# MSP430FR2475 register map
Vendor: msp430gen; File version: v0.4.0-28-gb0087ce-dirty
Registers are 16-bit, read-write, reset 0x0 unless marked. A register's access mark holds for its fields unless they carry their own. Offsets are from the block's base; [hi:lo] are bit positions; 'fields as' and 'values as' point back to an identical list.

## E_USCI_A1
Base 0x00000520
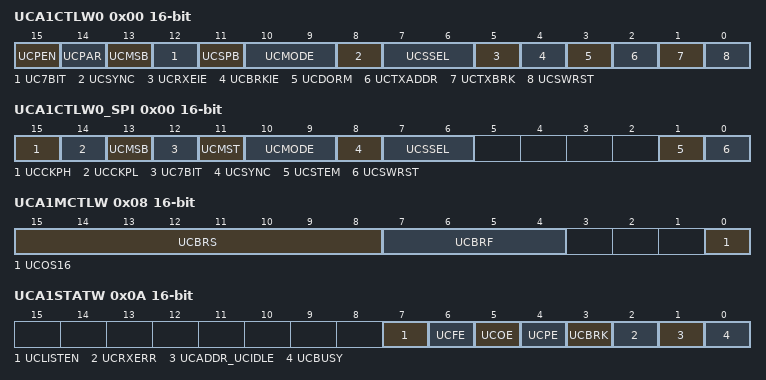
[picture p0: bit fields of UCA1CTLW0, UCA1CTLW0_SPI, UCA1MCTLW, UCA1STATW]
0x00 UCA1CTLW0 — eUSCI_Ax Control Word Register 0
  [15] UCPEN — Parity enable
    0=Parity disabled; 1=Parity enabled. Parity bit is generated (UCAxTXD) and expected (UCAxRXD). In address-bit multiprocessor mode, the address bit is included in the parity calculation.
  [14] UCPAR — Parity select
    0=ODD (Odd parity); 1=EVEN (Even parity)
  [13] UCMSB — MSB first select
    0=LSB first; 1=MSB first
  [12] UC7BIT — Character length
    0=8BIT (8-bit data); 1=7BIT (7-bit data)
  [11] UCSPB — Stop bit select
    0=One stop bit; 1=Two stop bits
  [10:9] UCMODE — eUSCI_A mode
    0=UART mode; 1=Idle-line multiprocessor mode; 2=Address-bit multiprocessor mode; 3=UART mode with automatic baud-rate detection
  [8] UCSYNC — Synchronous mode enable
    0=ASYNC (Asynchronous mode); 1=SYNC (Synchronous mode)
  [7:6] UCSSEL — eUSCI_A clock source select
    0=UCLK; 1=ACLK; 2=SMCLK; 3=SMCLK
  [5] UCRXEIE — Receive erroneous-character interrupt enable
    0=Erroneous characters rejected and UCRXIFG is not set; 1=Erroneous characters received set UCRXIFG
  [4] UCBRKIE — Receive break character interrupt enable
    0=Received break characters do not set UCRXIFG; 1=Received break characters set UCRXIFG
  [3] UCDORM — Dormant
    0=Not dormant. All received characters set UCRXIFG.; 1=Dormant. Only characters that are preceded by an idle-line or with address bit set UCRXIFG. In UART mode with automatic baud-rate detection, only the combination of a break and synch field sets UCRXIFG.
  [2] UCTXADDR — Transmit address
    0=Next frame transmitted is data; 1=Next frame transmitted is an address
  [1] UCTXBRK — Transmit break
    0=Next frame transmitted is not a break; 1=Next frame transmitted is a break or a break/synch
  [0] UCSWRST — Software reset enable
    0=DISABLE (Disabled. eUSCI_A reset released for operation); 1=ENABLE (Enabled. eUSCI_A logic held in reset state)
0x00 UCA1CTLW0_SPI (alternate view of UCA1CTLW0) — eUSCI_Ax Control Word Register 0
  [15] UCCKPH — Clock phase select
    0=Data is changed on the first UCLK edge and captured on the following edge; 1=Data is captured on the first UCLK edge and changed on the following edge
  [14] UCCKPL — Clock polarity select
    0=LOW (The inactive state is low); 1=HIGH (The inactive state is high)
  [13] UCMSB — MSB first select
    0=LSB first; 1=MSB first
  [12] UC7BIT — Character length
    0=8BIT (8-bit data); 1=7BIT (7-bit data)
  [11] UCMST — Master mode select
    0=SLAVE (Slave mode); 1=MASTER (Master mode)
  [10:9] UCMODE — eUSCI mode
    0=3-pin SPI; 1=4-pin SPI with UCxSTE active high: Slave enabled when UCxSTE = 1; 2=4-pin SPI with UCxSTE active low: Slave enabled when UCxSTE = 0; 3=I2C mode
  [8] UCSYNC — Synchronous mode enable
    0=ASYNC (Asynchronous mode); 1=SYNC (Synchronous mode)
  [7:6] UCSSEL — eUSCI_A clock source select
    1=ACLK; 2=SMCLK; 3=SMCLK
  [1] UCSTEM — STE mode select in master mode.
    0=STE pin is used to prevent conflicts with other masters; 1=STE pin is used to generate the enable signal for a 4-wire slave
  [0] UCSWRST — Software reset enable
    values as UCA1CTLW0.UCSWRST
0x02 UCA1CTLW1 — eUSCI_Ax Control Word Register 1
  [1:0] UCGLIT — Deglitch time
    0=Approximately 2 ns (equivalent of 1 delay element); 1=Approximately 50 ns; 2=Approximately 100 ns; 3=Approximately 200 ns
0x06 UCA1BRW — eUSCI_Ax Baud Rate Control Word Register
0x06 UCA1BRW_SPI (alternate view of UCA1BRW) — eUSCI_Ax Bit Rate Control Register 1
0x08 UCA1MCTLW — eUSCI_Ax Modulation Control Word Register
  [15:8] UCBRS — Second modulation stage select
  [7:4] UCBRF — First modulation stage select
  [0] UCOS16 — Oversampling mode enabled
    0=Disabled; 1=Enabled
0x0A UCA1STATW — eUSCI_Ax Status Register
  [7] UCLISTEN — Listen enable
    0=Disabled; 1=Enabled. UCAxTXD is internally fed back to the receiver
  [6] UCFE — Framing error flag
    0=No error; 1=Character received with low stop bit
  [5] UCOE — Overrun error flag
    0=No error; 1=Overrun error occurred
  [4] UCPE — Parity error flag. When UCPEN = 0, UCPE is read as 0. UCPE is cleared when UCAxRXBUF is read.
    0=No error; 1=Character received with parity error
  [3] UCBRK — Break detect flag
    0=No break condition; 1=Break condition occurred
  [2] UCRXERR — Receive error flag
    0=No receive errors detected; 1=Receive error detected
  [1] UCADDR_UCIDLE — Address received / Idle line detected
    0=UCADDR: Received character is data. UCIDLE: No idle line detected; 1=UCADDR: Received character is an address. UCIDLE: Idle line detected
  [0] UCBUSY ro — eUSCI_A busy
    0=IDLE (eUSCI_A inactive); 1=BUSY (eUSCI_A transmitting or receiving)
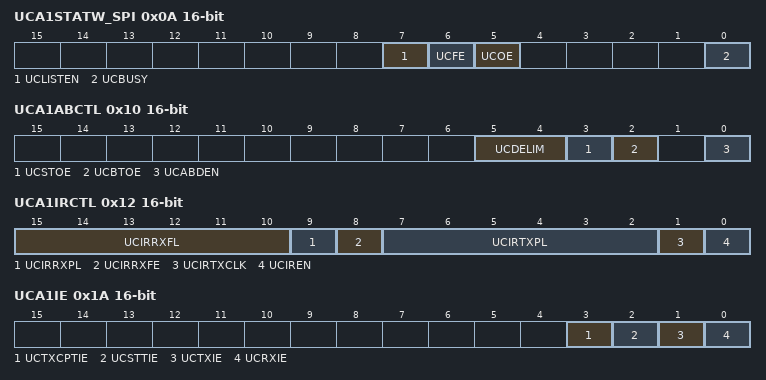
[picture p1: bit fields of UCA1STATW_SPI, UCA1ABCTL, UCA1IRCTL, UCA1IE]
0x0A UCA1STATW_SPI (alternate view of UCA1STATW)
  [7] UCLISTEN — Listen enable
    values as UCA1STATW.UCLISTEN
  [6] UCFE — Framing error flag
    0=No error; 1=Bus conflict occurred
  [5] UCOE — Overrun error flag
    0=No error; 1=Overrun error occurred
  [0] UCBUSY ro — eUSCI_A1 busy
    0=IDLE (eUSCI_A1 inactive); 1=BUSY (eUSCI_A1 transmitting or receiving)
0x0C UCA1RXBUF — eUSCI_Ax Receive Buffer Register
  [7:0] UCRXBUF ro — Receive data buffer
0x0C UCA1RXBUF_SPI (alternate view of UCA1RXBUF) — eUSCI_Ax Receive Buffer Register
  [7:0] UCRXBUF ro — Receive data buffer
0x0E UCA1TXBUF — eUSCI_Ax Transmit Buffer Register
  [7:0] UCTXBUF — Transmit data buffer
0x0E UCA1TXBUF_SPI (alternate view of UCA1TXBUF) — eUSCI_Ax Transmit Buffer Register
  [7:0] UCTXBUF — Transmit data buffer
0x10 UCA1ABCTL — eUSCI_Ax Auto Baud Rate Control Register
  [5:4] UCDELIM — Break/synch delimiter length
    0=1 bit time; 1=2 bit times; 2=3 bit times; 3=4 bit times
  [3] UCSTOE — Synch field time out error
    0=No error; 1=Length of synch field exceeded measurable time
  [2] UCBTOE — Break time out error
    0=No error; 1=Length of break field exceeded 22 bit times
  [0] UCABDEN — Automatic baud-rate detect enable
    0=Baud-rate detection disabled. Length of break and synch field is not measured.; 1=Baud-rate detection enabled. Length of break and synch field is measured and baud-rate settings are changed accordingly.
0x12 UCA1IRCTL — eUSCI_Ax IrDA Control Word Register
  [15:10] UCIRRXFL — Receive filter length
  [9] UCIRRXPL — IrDA receive input UCAxRXD polarity
    0=HIGH (IrDA transceiver delivers a high pulse when a light pulse is seen); 1=LOW (IrDA transceiver delivers a low pulse when a light pulse is seen)
  [8] UCIRRXFE — IrDA receive filter enabled
    0=Receive filter disabled; 1=Receive filter enabled
  [7:2] UCIRTXPL — Transmit pulse length
  [1] UCIRTXCLK — IrDA transmit pulse clock select
    0=BRCLK; 1=BITCLK16 when UCOS16 = 1. Otherwise, BRCLK.
  [0] UCIREN — IrDA encoder/decoder enable
    0=IrDA encoder/decoder disabled; 1=IrDA encoder/decoder enabled
0x1A UCA1IE — eUSCI_Ax Interrupt Enable Register
  [all] fields
    0=Interrupt disabled; 1=Interrupt enabled
  [3] UCTXCPTIE — Transmit complete interrupt enable
  [2] UCSTTIE — Start bit interrupt enable
  [1] UCTXIE — Transmit interrupt enable
  [0] UCRXIE — Receive interrupt enable
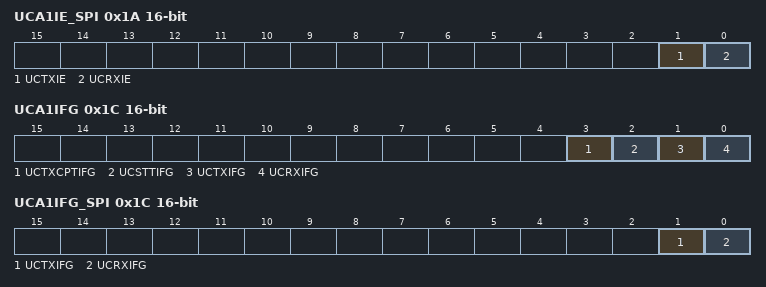
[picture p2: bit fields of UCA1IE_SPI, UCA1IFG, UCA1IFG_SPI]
0x1A UCA1IE_SPI (alternate view of UCA1IE) — eUSCI_Ax Interrupt Enable Register
  [1] UCTXIE — Transmit interrupt enable
    0=Interrupt disabled; 1=Interrupt enabled
  [0] UCRXIE — Receive interrupt enable
    0=Interrupt disabled; 1=Interrupt enabled
0x1C UCA1IFG — eUSCI_Ax Interrupt Flag Register
  [all] fields
    0=No interrupt pending; 1=Interrupt pending
  [3] UCTXCPTIFG — Transmit ready interrupt enable
  [2] UCSTTIFG — Start bit interrupt flag
  [1] UCTXIFG — Transmit interrupt flag
  [0] UCRXIFG — Receive interrupt flag
0x1C UCA1IFG_SPI (alternate view of UCA1IFG) — eUSCI_Ax Interrupt Flag Register
  [1] UCTXIFG — Transmit interrupt flag
    0=No interrupt pending; 1=Interrupt pending
  [0] UCRXIFG — Receive interrupt flag
    0=No interrupt pending; 1=Interrupt pending
0x1E UCA1IV — eUSCI_Ax Interrupt Vector Register
  [15:0] UCIV ro — eUSCI_A interrupt vector value
    0=NONE (No interrupt pending); 2=UCRXIFG (Interrupt Source: Receive buffer full; Interrupt Flag: UCRXIFG; Interrupt Priority: Highest); 4=UCTXIFG (Interrupt Source: Transmit buffer empty; Interrupt Flag: UCTXIFG); 6=UCSTTIFG (Interrupt Source: Start bit received; Interrupt Flag: UCSTTIFG); 8=UCTXCPTIFG (Interrupt Source: Transmit complete; Interrupt Flag: UCTXCPTIFG; Interrupt Priority: Lowest)
0x1E UCA1IV_SPI (alternate view of UCA1IV) — eUSCI_Ax Interrupt Vector Register
  [15:0] UCIV ro — eUSCI_A interrupt vector value
    0=NONE (No interrupt pending); 2=UCRXIFG (Interrupt Source: Data received; Interrupt Flag: UCRXIFG; Interrupt Priority: Highest); 4=UCTXIFG (Interrupt Source: Transmit buffer empty; Interrupt Flag: UCTXIFG; Interrupt Priority: Lowest)
